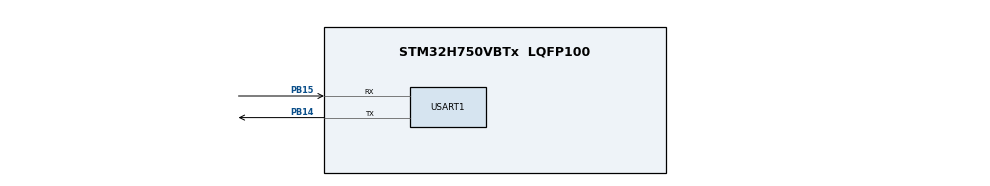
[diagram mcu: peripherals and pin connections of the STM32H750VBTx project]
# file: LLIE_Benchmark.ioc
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CORTEX_M7.CPU_DCache=Enabled
CORTEX_M7.CPU_ICache=Enabled
CORTEX_M7.default_mode_Activation=1
Mcu.Family=STM32H7
Mcu.Name=STM32H750VBTx
Mcu.Package=LQFP100
NVIC.PriorityGroup=NVIC_PRIORITYGROUP_4
PA13\ (JTMS/SWDIO).Mode=Serial_Wire
PA13\ (JTMS/SWDIO).Signal=DEBUG_JTMS-SWDIO
PA14\ (JTCK/SWCLK).Mode=Serial_Wire
PA14\ (JTCK/SWCLK).Signal=DEBUG_JTCK-SWCLK
PB14.Mode=Asynchronous
PB14.Signal=USART1_TX
PB15.Mode=Asynchronous
PB15.Signal=USART1_RX
PH0-OSC_IN\ (PH0).Mode=HSE-External-Oscillator
PH0-OSC_IN\ (PH0).Signal=RCC_OSC_IN
PH1-OSC_OUT\ (PH1).Mode=HSE-External-Oscillator
PH1-OSC_OUT\ (PH1).Signal=RCC_OSC_OUT
ProjectManager.HeapSize=0x200
ProjectManager.StackSize=0x400
ProjectManager.TargetToolchain=STM32CubeIDE
RCC.ADCFreq_Value=50390625
RCC.APB1Freq_Value=120000000
RCC.APB2Freq_Value=120000000
RCC.APB3Freq_Value=120000000
RCC.APB4Freq_Value=120000000
RCC.CortexFreq_Value=480000000
RCC.D1PPRE=RCC_APB3_DIV2
RCC.D2PPRE1=RCC_APB1_DIV2
RCC.D2PPRE2=RCC_APB2_DIV2
RCC.D3PPRE=RCC_APB4_DIV2
RCC.DIVM1=5
RCC.DIVN1=192
RCC.EnbaleCSS=true
RCC.HCLKFreq_Value=240000000
RCC.HPRE=RCC_HCLK_DIV2
RCC.PLLSourceVirtual=RCC_PLLSOURCE_HSE
RCC.SYSCLKFreq_VALUE=480000000
RCC.SYSCLKSource=RCC_SYSCLKSOURCE_PLLCLK
RCC.USBFreq_Value=480000000
USART1.VirtualMode-Asynchronous=VM_ASYNC
VP_CRC_VS_CRC.Mode=CRC_Activate
VP_MEMORYMAP_VS_MEMORYMAP.Mode=CurAppReg
board=custom

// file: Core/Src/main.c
/* USER CODE BEGIN Header */
/**
  ******************************************************************************
  * @file           : main.c
  * @brief          : Main program body
  ******************************************************************************
  * @attention
  *
  * Copyright (c) 2026 STMicroelectronics.
  * All rights reserved.
  *
  * This software is licensed under terms that can be found in the LICENSE file
  * in the root directory of this software component.
  * If no LICENSE file comes with this software, it is provided AS-IS.
  *
  ******************************************************************************
  */
/* USER CODE END Header */
#include "main.h"

/* USER CODE BEGIN Includes */
#include "llieai.h"
#include "llieai_data.h"
#include "llieai_data_params.h"

#include <errno.h>
#include <stdio.h>
#include <string.h>
#include <sys/stat.h>

/* USER CODE END Includes */

CRC_HandleTypeDef hcrc;

UART_HandleTypeDef huart1;

/* USER CODE BEGIN PV */
AI_ALIGNED(4) static ai_u8 ai_activations[AI_LLIEAI_DATA_ACTIVATIONS_SIZE];
AI_ALIGNED(4) static ai_u8 ai_input_data[AI_LLIEAI_IN_1_SIZE_BYTES];
AI_ALIGNED(4) static ai_u8 ai_output_data[AI_LLIEAI_OUT_1_SIZE_BYTES];

static ai_handle ai_network = AI_HANDLE_NULL;
static ai_buffer *ai_input;
static ai_buffer *ai_output;

/* USER CODE END PV */

void SystemClock_Config(void);
static void MPU_Config(void);
static void MX_GPIO_Init(void);
static void MX_CRC_Init(void);
static void MX_USART1_UART_Init(void);

/* USER CODE BEGIN 0 */
int _write(int file, char *ptr, int len)
{
  (void)file;
  HAL_UART_Transmit(&huart1, (uint8_t *)ptr, (uint16_t)len, HAL_MAX_DELAY);
  return len;
}

int _read(int file, char *ptr, int len)
{
  (void)file;
  (void)ptr;
  (void)len;
  errno = ENOSYS;
  return -1;
}

int _close(int file)
{
  (void)file;
  errno = ENOSYS;
  return -1;
}

int _fstat(int file, struct stat *st)
{
  (void)file;
  st->st_mode = S_IFCHR;
  return 0;
}

int _isatty(int file)
{
  (void)file;
  return 1;
}

int _lseek(int file, int ptr, int dir)
{
  (void)file;
  (void)ptr;
  (void)dir;
  return 0;
}

static void dwt_counter_init(void)
{
  CoreDebug->DEMCR |= CoreDebug_DEMCR_TRCENA_Msk;
  DWT->CYCCNT = 0;
  DWT->CTRL |= DWT_CTRL_CYCCNTENA_Msk;
}

static uint32_t dwt_cycles(void)
{
  return DWT->CYCCNT;
}

static int llie_ai_init(void)
{
  const ai_handle activations[] = {
    AI_HANDLE_PTR(ai_activations)
  };

  ai_error err = ai_llieai_create_and_init(
      &ai_network,
      activations,
      AI_LLIEAI_DATA_WEIGHTS_TABLE_GET());

  if (err.type != AI_ERROR_NONE) {
    printf("AI init failed: type=%d code=%d\r\n", err.type, err.code);
    return -1;
  }

  ai_input = ai_llieai_inputs_get(ai_network, NULL);
  ai_output = ai_llieai_outputs_get(ai_network, NULL);
  ai_input[0].data = AI_HANDLE_PTR(ai_input_data);
  ai_output[0].data = AI_HANDLE_PTR(ai_output_data);

  printf("AI init OK\r\n");
  printf("input=%lu bytes output=%lu bytes activations=%lu bytes\r\n",
      (uint32_t)AI_LLIEAI_IN_1_SIZE_BYTES,
      (uint32_t)AI_LLIEAI_OUT_1_SIZE_BYTES,
      (uint32_t)AI_LLIEAI_DATA_ACTIVATIONS_SIZE);
  return 0;
}

static void fill_test_input(void)
{
  for (uint32_t i = 0; i < AI_LLIEAI_IN_1_SIZE_BYTES; ++i) {
    ai_input_data[i] = 32U;
  }
}

static void run_llie_benchmark(void)
{
  const uint32_t warmup_runs = 10;
  const uint32_t measure_runs = 100;
  uint64_t sum_cycles = 0;
  uint32_t min_cycles = 0xFFFFFFFFU;
  uint32_t max_cycles = 0;

  fill_test_input();
  memset(ai_output_data, 0, sizeof(ai_output_data));

  for (uint32_t i = 0; i < warmup_runs; ++i) {
    if (ai_llieai_run(ai_network, ai_input, ai_output) != 1) {
      ai_error err = ai_llieai_get_error(ai_network);
      printf("AI warmup failed: type=%d code=%d\r\n", err.type, err.code);
      return;
    }
  }

  for (uint32_t i = 0; i < measure_runs; ++i) {
    uint32_t start_cycles = dwt_cycles();
    ai_i32 batch = ai_llieai_run(ai_network, ai_input, ai_output);
    uint32_t elapsed_cycles = dwt_cycles() - start_cycles;

    if (batch != 1) {
      ai_error err = ai_llieai_get_error(ai_network);
      printf("AI run failed: type=%d code=%d\r\n", err.type, err.code);
      return;
    }

    if (elapsed_cycles < min_cycles) {
      min_cycles = elapsed_cycles;
    }
    if (elapsed_cycles > max_cycles) {
      max_cycles = elapsed_cycles;
    }
    sum_cycles += elapsed_cycles;
  }

  uint32_t avg_cycles = (uint32_t)(sum_cycles / measure_runs);
  uint32_t cycles_per_us = SystemCoreClock / 1000000U;
  uint32_t avg_us = avg_cycles / cycles_per_us;
  uint32_t min_us = min_cycles / cycles_per_us;
  uint32_t max_us = max_cycles / cycles_per_us;
  uint32_t fps_x100 = (avg_us > 0U) ? (100000000U / avg_us) : 0U;

  printf("\r\nLLIE model-only benchmark\r\n");
  printf("SystemCoreClock=%lu Hz\r\n", SystemCoreClock);
  printf("runs=%lu warmup=%lu\r\n", measure_runs, warmup_runs);
  printf("min_cycles=%lu min_us=%lu\r\n", min_cycles, min_us);
  printf("avg_cycles=%lu avg_us=%lu\r\n", avg_cycles, avg_us);
  printf("max_cycles=%lu max_us=%lu\r\n", max_cycles, max_us);
  printf("fps=%lu.%02lu\r\n", fps_x100 / 100U, fps_x100 % 100U);
  printf("output_sample=%u,%u,%u,%u\r\n",
      ai_output_data[0], ai_output_data[1], ai_output_data[2], ai_output_data[3]);
}

/* USER CODE END 0 */

int main(void)
{

  /* MPU Configuration--------------------------------------------------------*/
  MPU_Config();

  /* Enable the CPU Cache */

  /* Enable I-Cache---------------------------------------------------------*/
  SCB_EnableICache();

  /* Enable D-Cache---------------------------------------------------------*/
  SCB_EnableDCache();

  /* MCU Configuration--------------------------------------------------------*/

  /* Reset of all peripherals, Initializes the Flash interface and the Systick. */
  HAL_Init();

  /* Configure the system clock */
  SystemClock_Config();

  /* Initialize all configured peripherals */
  MX_GPIO_Init();
  MX_CRC_Init();
  MX_USART1_UART_Init();
  /* USER CODE BEGIN 2 */
  dwt_counter_init();
  HAL_Delay(100);

  printf("\r\nBoot LLIE_Benchmark\r\n");
  printf("SystemCoreClock=%lu Hz\r\n", SystemCoreClock);

  if (llie_ai_init() == 0) {
    run_llie_benchmark();
  }

  /* USER CODE END 2 */

  /* Infinite loop */
  while (1)
  {

  }
}

void SystemClock_Config(void)
{
  RCC_OscInitTypeDef RCC_OscInitStruct = {0};
  RCC_ClkInitTypeDef RCC_ClkInitStruct = {0};

  /** Supply configuration update enable
  */
  HAL_PWREx_ConfigSupply(PWR_LDO_SUPPLY);

  /** Configure the main internal regulator output voltage
  */
  __HAL_PWR_VOLTAGESCALING_CONFIG(PWR_REGULATOR_VOLTAGE_SCALE0);

  while(!__HAL_PWR_GET_FLAG(PWR_FLAG_VOSRDY)) {}

  /** Initializes the RCC Oscillators according to the specified parameters
  * in the RCC_OscInitTypeDef structure.
  */
  RCC_OscInitStruct.OscillatorType = RCC_OSCILLATORTYPE_HSE;
  RCC_OscInitStruct.HSEState = RCC_HSE_ON;
  RCC_OscInitStruct.PLL.PLLState = RCC_PLL_ON;
  RCC_OscInitStruct.PLL.PLLSource = RCC_PLLSOURCE_HSE;
  RCC_OscInitStruct.PLL.PLLM = 5;
  RCC_OscInitStruct.PLL.PLLN = 192;
  RCC_OscInitStruct.PLL.PLLP = 2;
  RCC_OscInitStruct.PLL.PLLQ = 20;
  RCC_OscInitStruct.PLL.PLLR = 2;
  RCC_OscInitStruct.PLL.PLLRGE = RCC_PLL1VCIRANGE_1;
  RCC_OscInitStruct.PLL.PLLVCOSEL = RCC_PLL1VCOWIDE;
  RCC_OscInitStruct.PLL.PLLFRACN = 0;
  if (HAL_RCC_OscConfig(&RCC_OscInitStruct) != HAL_OK)
  {
    Error_Handler();
  }

  /** Initializes the CPU, AHB and APB buses clocks
  */
  RCC_ClkInitStruct.ClockType = RCC_CLOCKTYPE_HCLK|RCC_CLOCKTYPE_SYSCLK
                              |RCC_CLOCKTYPE_PCLK1|RCC_CLOCKTYPE_PCLK2
                              |RCC_CLOCKTYPE_D3PCLK1|RCC_CLOCKTYPE_D1PCLK1;
  RCC_ClkInitStruct.SYSCLKSource = RCC_SYSCLKSOURCE_PLLCLK;
  RCC_ClkInitStruct.SYSCLKDivider = RCC_SYSCLK_DIV1;
  RCC_ClkInitStruct.AHBCLKDivider = RCC_HCLK_DIV2;
  RCC_ClkInitStruct.APB3CLKDivider = RCC_APB3_DIV2;
  RCC_ClkInitStruct.APB1CLKDivider = RCC_APB1_DIV2;
  RCC_ClkInitStruct.APB2CLKDivider = RCC_APB2_DIV2;
  RCC_ClkInitStruct.APB4CLKDivider = RCC_APB4_DIV2;

  if (HAL_RCC_ClockConfig(&RCC_ClkInitStruct, FLASH_LATENCY_4) != HAL_OK)
  {
    Error_Handler();
  }

  /** Enables the Clock Security System
  */
  HAL_RCC_EnableCSS();
}

static void MX_CRC_Init(void)
{

  hcrc.Instance = CRC;
  hcrc.Init.DefaultPolynomialUse = DEFAULT_POLYNOMIAL_ENABLE;
  hcrc.Init.DefaultInitValueUse = DEFAULT_INIT_VALUE_ENABLE;
  hcrc.Init.InputDataInversionMode = CRC_INPUTDATA_INVERSION_NONE;
  hcrc.Init.OutputDataInversionMode = CRC_OUTPUTDATA_INVERSION_DISABLE;
  hcrc.InputDataFormat = CRC_INPUTDATA_FORMAT_BYTES;
  if (HAL_CRC_Init(&hcrc) != HAL_OK)
  {
    Error_Handler();
  }

}

static void MX_USART1_UART_Init(void)
{

  huart1.Instance = USART1;
  huart1.Init.BaudRate = 115200;
  huart1.Init.WordLength = UART_WORDLENGTH_8B;
  huart1.Init.StopBits = UART_STOPBITS_1;
  huart1.Init.Parity = UART_PARITY_NONE;
  huart1.Init.Mode = UART_MODE_TX_RX;
  huart1.Init.HwFlowCtl = UART_HWCONTROL_NONE;
  huart1.Init.OverSampling = UART_OVERSAMPLING_16;
  huart1.Init.OneBitSampling = UART_ONE_BIT_SAMPLE_DISABLE;
  huart1.Init.ClockPrescaler = UART_PRESCALER_DIV1;
  huart1.AdvancedInit.AdvFeatureInit = UART_ADVFEATURE_NO_INIT;
  if (HAL_UART_Init(&huart1) != HAL_OK)
  {
    Error_Handler();
  }
  if (HAL_UARTEx_SetTxFifoThreshold(&huart1, UART_TXFIFO_THRESHOLD_1_8) != HAL_OK)
  {
    Error_Handler();
  }
  if (HAL_UARTEx_SetRxFifoThreshold(&huart1, UART_RXFIFO_THRESHOLD_1_8) != HAL_OK)
  {
    Error_Handler();
  }
  if (HAL_UARTEx_DisableFifoMode(&huart1) != HAL_OK)
  {
    Error_Handler();
  }

}

static void MX_GPIO_Init(void)
{

  /* GPIO Ports Clock Enable */
  __HAL_RCC_GPIOH_CLK_ENABLE();
  __HAL_RCC_GPIOB_CLK_ENABLE();
  __HAL_RCC_GPIOA_CLK_ENABLE();

}

 /* MPU Configuration */

void MPU_Config(void)
{
  MPU_Region_InitTypeDef MPU_InitStruct = {0};

  /* Disables the MPU */
  HAL_MPU_Disable();

  /** Initializes and configures the Region and the memory to be protected
  */
  MPU_InitStruct.Enable = MPU_REGION_ENABLE;
  MPU_InitStruct.Number = MPU_REGION_NUMBER0;
  MPU_InitStruct.BaseAddress = 0x0;
  MPU_InitStruct.Size = MPU_REGION_SIZE_4GB;
  MPU_InitStruct.SubRegionDisable = 0x87;
  MPU_InitStruct.TypeExtField = MPU_TEX_LEVEL0;
  MPU_InitStruct.AccessPermission = MPU_REGION_NO_ACCESS;
  MPU_InitStruct.DisableExec = MPU_INSTRUCTION_ACCESS_DISABLE;
  MPU_InitStruct.IsShareable = MPU_ACCESS_SHAREABLE;
  MPU_InitStruct.IsCacheable = MPU_ACCESS_NOT_CACHEABLE;
  MPU_InitStruct.IsBufferable = MPU_ACCESS_NOT_BUFFERABLE;

  HAL_MPU_ConfigRegion(&MPU_InitStruct);
  /* Enables the MPU */
  HAL_MPU_Enable(MPU_PRIVILEGED_DEFAULT);

}

void Error_Handler(void)
{
  __disable_irq();
  while (1)
  {
  }
}
